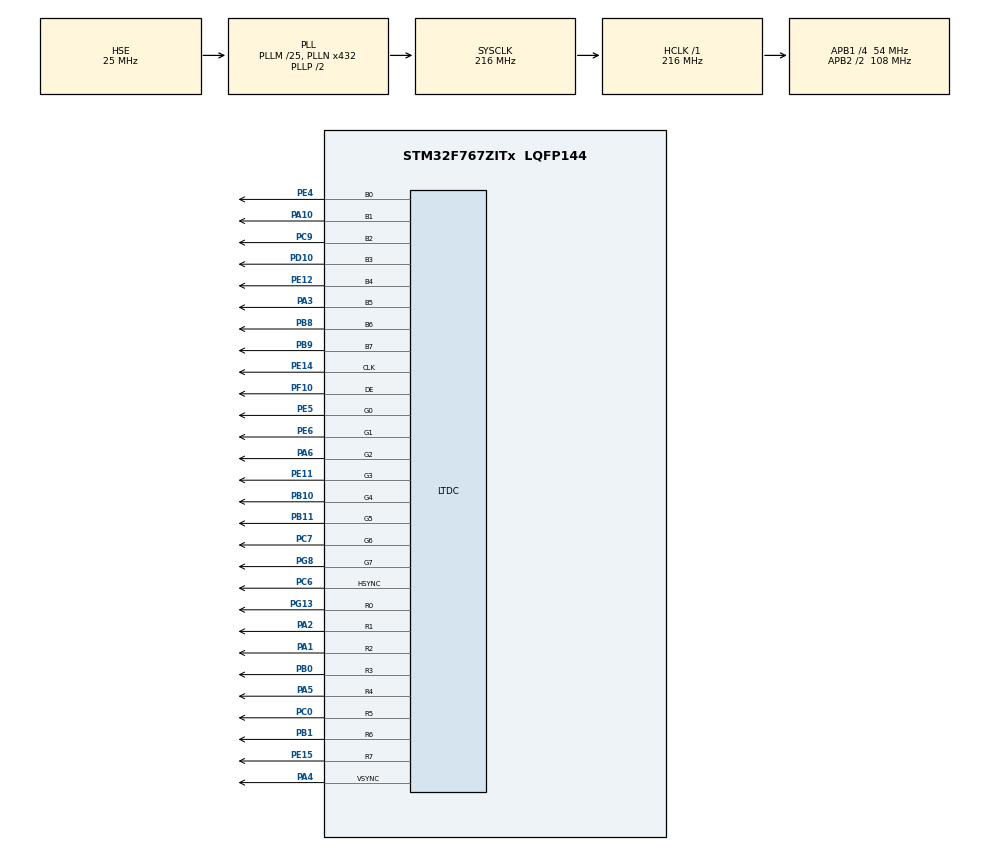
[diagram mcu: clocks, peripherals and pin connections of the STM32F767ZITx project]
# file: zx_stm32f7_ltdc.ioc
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LTDC.ActiveH=272
LTDC.ActiveW=384
LTDC.Alpha0_L0=0
LTDC.Alpha_L0=255
LTDC.BlendingFactor1_L0=LTDC_BLENDING_FACTOR1_PAxCA
LTDC.BlendingFactor2_L0=LTDC_BLENDING_FACTOR2_PAxCA
LTDC.DEPolarity=LTDC_DEPOLARITY_AL
LTDC.HBP=43
LTDC.HFP=8
LTDC.HSPolarity=LTDC_HSPOLARITY_AL
LTDC.HSync=14
LTDC.ImageHeight_L0=192
LTDC.ImageWidth_L0=256
LTDC.Layers=0
LTDC.PixelFormat_L0=LTDC_PIXEL_FORMAT_RGB565
LTDC.VBP=12
LTDC.VFP=4
LTDC.VSPolarity=LTDC_VSPOLARITY_AL
LTDC.VSync=25
LTDC.WindowX0_L0=64
LTDC.WindowX1_L0=320
LTDC.WindowY0_L0=40
LTDC.WindowY1_L0=232
Mcu.Family=STM32F7
Mcu.Name=STM32F767ZITx
Mcu.Package=LQFP144
NVIC.PriorityGroup=NVIC_PRIORITYGROUP_4
PA1.GPIO_Speed=GPIO_SPEED_FREQ_VERY_HIGH
PA1.Mode=RGB888
PA1.Signal=LTDC_R2
PA10.GPIO_Speed=GPIO_SPEED_FREQ_VERY_HIGH
PA10.Mode=RGB888
PA10.Signal=LTDC_B1
PA2.GPIO_Speed=GPIO_SPEED_FREQ_VERY_HIGH
PA2.Mode=RGB888
PA2.Signal=LTDC_R1
PA3.GPIO_Speed=GPIO_SPEED_FREQ_VERY_HIGH
PA3.Mode=RGB888
PA3.Signal=LTDC_B5
PA4.GPIO_Speed=GPIO_SPEED_FREQ_VERY_HIGH
PA4.Mode=RGB888
PA4.Signal=LTDC_VSYNC
PA5.GPIO_Speed=GPIO_SPEED_FREQ_VERY_HIGH
PA5.Mode=RGB888
PA5.Signal=LTDC_R4
PA6.GPIO_Speed=GPIO_SPEED_FREQ_VERY_HIGH
PA6.Mode=RGB888
PA6.Signal=LTDC_G2
PB0.GPIO_Speed=GPIO_SPEED_FREQ_VERY_HIGH
PB0.Mode=RGB888
PB0.Signal=LTDC_R3
PB1.GPIO_Speed=GPIO_SPEED_FREQ_VERY_HIGH
PB1.Mode=RGB888
PB1.Signal=LTDC_R6
PB10.GPIO_Speed=GPIO_SPEED_FREQ_VERY_HIGH
PB10.Mode=RGB888
PB10.Signal=LTDC_G4
PB11.GPIO_Speed=GPIO_SPEED_FREQ_VERY_HIGH
PB11.Mode=RGB888
PB11.Signal=LTDC_G5
PB8.GPIO_Speed=GPIO_SPEED_FREQ_VERY_HIGH
PB8.Mode=RGB888
PB8.Signal=LTDC_B6
PB9.GPIO_Speed=GPIO_SPEED_FREQ_VERY_HIGH
PB9.Mode=RGB888
PB9.Signal=LTDC_B7
PC0.GPIO_Speed=GPIO_SPEED_FREQ_VERY_HIGH
PC0.Mode=RGB888
PC0.Signal=LTDC_R5
PC6.GPIO_Speed=GPIO_SPEED_FREQ_VERY_HIGH
PC6.Mode=RGB888
PC6.Signal=LTDC_HSYNC
PC7.GPIO_Speed=GPIO_SPEED_FREQ_VERY_HIGH
PC7.Mode=RGB888
PC7.Signal=LTDC_G6
PC9.GPIO_Speed=GPIO_SPEED_FREQ_VERY_HIGH
PC9.Mode=RGB888
PC9.Signal=LTDC_B2
PD10.GPIO_Speed=GPIO_SPEED_FREQ_VERY_HIGH
PD10.Mode=RGB888
PD10.Signal=LTDC_B3
PE11.GPIO_Speed=GPIO_SPEED_FREQ_VERY_HIGH
PE11.Mode=RGB888
PE11.Signal=LTDC_G3
PE12.GPIO_Speed=GPIO_SPEED_FREQ_VERY_HIGH
PE12.Mode=RGB888
PE12.Signal=LTDC_B4
PE14.GPIO_Speed=GPIO_SPEED_FREQ_VERY_HIGH
PE14.Mode=RGB888
PE14.Signal=LTDC_CLK
PE15.GPIO_Speed=GPIO_SPEED_FREQ_VERY_HIGH
PE15.Mode=RGB888
PE15.Signal=LTDC_R7
PE4.GPIO_Speed=GPIO_SPEED_FREQ_VERY_HIGH
PE4.Mode=RGB888
PE4.Signal=LTDC_B0
PE5.GPIO_Speed=GPIO_SPEED_FREQ_VERY_HIGH
PE5.Mode=RGB888
PE5.Signal=LTDC_G0
PE6.GPIO_Speed=GPIO_SPEED_FREQ_VERY_HIGH
PE6.Mode=RGB888
PE6.Signal=LTDC_G1
PF10.GPIO_Speed=GPIO_SPEED_FREQ_VERY_HIGH
PF10.Mode=RGB888
PF10.Signal=LTDC_DE
PG13.GPIO_Speed=GPIO_SPEED_FREQ_VERY_HIGH
PG13.Mode=RGB888
PG13.Signal=LTDC_R0
PG8.GPIO_Speed=GPIO_SPEED_FREQ_VERY_HIGH
PG8.Mode=RGB888
PG8.Signal=LTDC_G7
PH0/OSC_IN.Mode=HSE-External-Oscillator
PH0/OSC_IN.Signal=RCC_OSC_IN
PH1/OSC_OUT.Mode=HSE-External-Oscillator
PH1/OSC_OUT.Signal=RCC_OSC_OUT
ProjectManager.HeapSize=0x200
ProjectManager.StackSize=0x400
ProjectManager.TargetToolchain=SW4STM32
RCC.AHBFreq_Value=216000000
RCC.APB1CLKDivider=RCC_HCLK_DIV4
RCC.APB1Freq_Value=54000000
RCC.APB1TimFreq_Value=108000000
RCC.APB2CLKDivider=RCC_HCLK_DIV2
RCC.APB2Freq_Value=108000000
RCC.APB2TimFreq_Value=216000000
RCC.CortexFreq_Value=216000000
RCC.HCLKFreq_Value=216000000
RCC.HSE_VALUE=25000000
RCC.HSI_VALUE=16000000
RCC.LSE_VALUE=32768
RCC.PLLM=25
RCC.PLLN=432
RCC.PLLQ=9
RCC.PLLSAIN=224
RCC.PLLSAIR=4
RCC.PLLSAIRDiv=RCC_PLLSAIDIVR_8
RCC.PLLSourceVirtual=RCC_PLLSOURCE_HSE
RCC.SYSCLKFreq_VALUE=216000000
RCC.SYSCLKSource=RCC_SYSCLKSOURCE_PLLCLK
RCC.USBFreq_Value=48000000
RCC.VCOOutputFreq_Value=432000000
VP_RNG_VS_RNG.Mode=RNG_Activate
board=zx_stm32f7_ltdc

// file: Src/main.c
/**
  ******************************************************************************
  * File Name          : main.c
  * Description        : Main program body
  ******************************************************************************
  ** This notice applies to any and all portions of this file
  * that are not between comment pairs USER CODE BEGIN and
  * USER CODE END. Other portions of this file, whether
  * inserted by the user or by software development tools
  * are owned by their respective copyright owners.
  *
  * COPYRIGHT(c) 2018 STMicroelectronics
  *
  * Redistribution and use in source and binary forms, with or without modification,
  * are permitted provided that the following conditions are met:
  *   1. Redistributions of source code must retain the above copyright notice,
  *      this list of conditions and the following disclaimer.
  *   2. Redistributions in binary form must reproduce the above copyright notice,
  *      this list of conditions and the following disclaimer in the documentation
  *      and/or other materials provided with the distribution.
  *   3. Neither the name of STMicroelectronics nor the names of its contributors
  *      may be used to endorse or promote products derived from this software
  *      without specific prior written permission.
  *
  * THIS SOFTWARE IS PROVIDED BY THE COPYRIGHT HOLDERS AND CONTRIBUTORS "AS IS"
  * AND ANY EXPRESS OR IMPLIED WARRANTIES, INCLUDING, BUT NOT LIMITED TO, THE
  * IMPLIED WARRANTIES OF MERCHANTABILITY AND FITNESS FOR A PARTICULAR PURPOSE ARE
  * DISCLAIMED. IN NO EVENT SHALL THE COPYRIGHT HOLDER OR CONTRIBUTORS BE LIABLE
  * FOR ANY DIRECT, INDIRECT, INCIDENTAL, SPECIAL, EXEMPLARY, OR CONSEQUENTIAL
  * DAMAGES (INCLUDING, BUT NOT LIMITED TO, PROCUREMENT OF SUBSTITUTE GOODS OR
  * SERVICES; LOSS OF USE, DATA, OR PROFITS; OR BUSINESS INTERRUPTION) HOWEVER
  * CAUSED AND ON ANY THEORY OF LIABILITY, WHETHER IN CONTRACT, STRICT LIABILITY,
  * OR TORT (INCLUDING NEGLIGENCE OR OTHERWISE) ARISING IN ANY WAY OUT OF THE USE
  * OF THIS SOFTWARE, EVEN IF ADVISED OF THE POSSIBILITY OF SUCH DAMAGE.
  *
  ******************************************************************************
  */

#include "main.h"
#include "stm32f7xx_hal.h"
#include "ltdc.h"
#include "rng.h"
#include "gpio.h"

/* USER CODE BEGIN PV */
/* Private variables ---------------------------------------------------------*/

uint16_t screen_buf[49152]={0x0000};
uint16_t screen_counter;
uint16_t line=0;
uint16_t color=0xffff;
uint32_t border;

/* USER CODE END PV */

void SystemClock_Config(void);

/* USER CODE BEGIN PFP */
/* Private function prototypes -----------------------------------------------*/

/* USER CODE END PFP */

int main(void)
{

  /* MCU Configuration----------------------------------------------------------*/

  /* Reset of all peripherals, Initializes the Flash interface and the Systick. */
  HAL_Init();

  /* Configure the system clock */
  SystemClock_Config();

  /* Initialize all configured peripherals */
  MX_GPIO_Init();
  MX_LTDC_Init();
  MX_RNG_Init();

  /* USER CODE BEGIN 2 */
  HAL_LTDC_SetAddress(&hltdc, (uint32_t)&screen_buf, 0);

  /* USER CODE END 2 */

  /* Infinite loop */
  /* USER CODE BEGIN WHILE */
  while (1)
  {
	  for (line=0; line<49152; line=line+256)
	  {
		  for (screen_counter=0; screen_counter<256; screen_counter++)
		  {
			  screen_buf[(screen_counter+line)]=color;
		  }
		  color=HAL_RNG_GetRandomNumber(&hrng);
		  HAL_Delay (1);
	  }
	  LTDC->BCCR=0xffffff&HAL_RNG_GetRandomNumber(&hrng);

  /* USER CODE END WHILE */

  }

}

/** System Clock Configuration
*/
void SystemClock_Config(void)
{

  RCC_OscInitTypeDef RCC_OscInitStruct;
  RCC_ClkInitTypeDef RCC_ClkInitStruct;
  RCC_PeriphCLKInitTypeDef PeriphClkInitStruct;

    /**Configure the main internal regulator output voltage
    */
  __HAL_RCC_PWR_CLK_ENABLE();

  __HAL_PWR_VOLTAGESCALING_CONFIG(PWR_REGULATOR_VOLTAGE_SCALE1);

    /**Initializes the CPU, AHB and APB busses clocks
    */
  RCC_OscInitStruct.OscillatorType = RCC_OSCILLATORTYPE_HSE;
  RCC_OscInitStruct.HSEState = RCC_HSE_ON;
  RCC_OscInitStruct.PLL.PLLState = RCC_PLL_ON;
  RCC_OscInitStruct.PLL.PLLSource = RCC_PLLSOURCE_HSE;
  RCC_OscInitStruct.PLL.PLLM = 25;
  RCC_OscInitStruct.PLL.PLLN = 432;
  RCC_OscInitStruct.PLL.PLLP = RCC_PLLP_DIV2;
  RCC_OscInitStruct.PLL.PLLQ = 9;
  if (HAL_RCC_OscConfig(&RCC_OscInitStruct) != HAL_OK)
  {
    _Error_Handler(__FILE__, __LINE__);
  }

    /**Activate the Over-Drive mode
    */
  if (HAL_PWREx_EnableOverDrive() != HAL_OK)
  {
    _Error_Handler(__FILE__, __LINE__);
  }

    /**Initializes the CPU, AHB and APB busses clocks
    */
  RCC_ClkInitStruct.ClockType = RCC_CLOCKTYPE_HCLK|RCC_CLOCKTYPE_SYSCLK
                              |RCC_CLOCKTYPE_PCLK1|RCC_CLOCKTYPE_PCLK2;
  RCC_ClkInitStruct.SYSCLKSource = RCC_SYSCLKSOURCE_PLLCLK;
  RCC_ClkInitStruct.AHBCLKDivider = RCC_SYSCLK_DIV1;
  RCC_ClkInitStruct.APB1CLKDivider = RCC_HCLK_DIV4;
  RCC_ClkInitStruct.APB2CLKDivider = RCC_HCLK_DIV2;

  if (HAL_RCC_ClockConfig(&RCC_ClkInitStruct, FLASH_LATENCY_7) != HAL_OK)
  {
    _Error_Handler(__FILE__, __LINE__);
  }

  PeriphClkInitStruct.PeriphClockSelection = RCC_PERIPHCLK_LTDC|RCC_PERIPHCLK_CLK48;
  PeriphClkInitStruct.PLLSAI.PLLSAIN = 224;
  PeriphClkInitStruct.PLLSAI.PLLSAIR = 4;
  PeriphClkInitStruct.PLLSAI.PLLSAIQ = 2;
  PeriphClkInitStruct.PLLSAI.PLLSAIP = RCC_PLLSAIP_DIV2;
  PeriphClkInitStruct.PLLSAIDivQ = 1;
  PeriphClkInitStruct.PLLSAIDivR = RCC_PLLSAIDIVR_8;
  PeriphClkInitStruct.Clk48ClockSelection = RCC_CLK48SOURCE_PLL;
  if (HAL_RCCEx_PeriphCLKConfig(&PeriphClkInitStruct) != HAL_OK)
  {
    _Error_Handler(__FILE__, __LINE__);
  }

    /**Configure the Systick interrupt time
    */
  HAL_SYSTICK_Config(HAL_RCC_GetHCLKFreq()/1000);

    /**Configure the Systick
    */
  HAL_SYSTICK_CLKSourceConfig(SYSTICK_CLKSOURCE_HCLK);

  /* SysTick_IRQn interrupt configuration */
  HAL_NVIC_SetPriority(SysTick_IRQn, 0, 0);
}

void _Error_Handler(char * file, int line)
{
  while(1)
  {
  }
}

/************************ (C) COPYRIGHT STMicroelectronics *****END OF FILE****/
